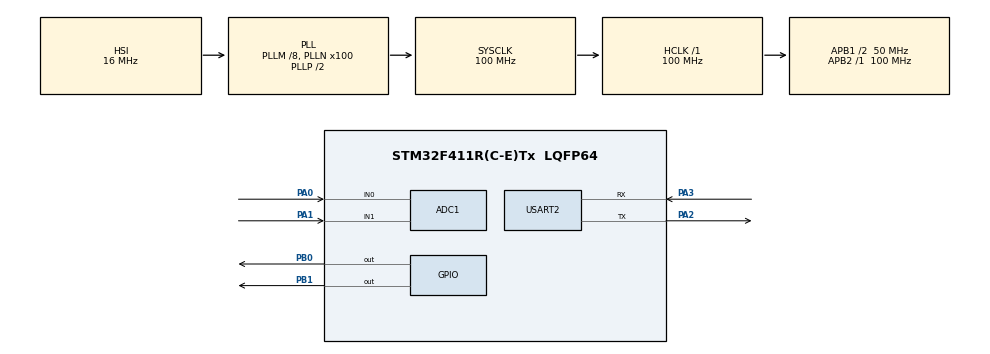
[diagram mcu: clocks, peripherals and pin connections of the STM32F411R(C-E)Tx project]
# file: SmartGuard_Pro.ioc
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ADC1.Channel-1\#ChannelRegularConversion=ADC_CHANNEL_0
ADC1.Channel-2\#ChannelRegularConversion=ADC_CHANNEL_1
ADC1.ContinuousConvMode=ENABLE
ADC1.NbrOfConversion=2
ADC1.NbrOfConversionFlag=1
ADC1.Rank-1\#ChannelRegularConversion=1
ADC1.Rank-2\#ChannelRegularConversion=2
ADC1.SamplingTime-1\#ChannelRegularConversion=ADC_SAMPLETIME_3CYCLES
ADC1.SamplingTime-2\#ChannelRegularConversion=ADC_SAMPLETIME_112CYCLES
ADC1.ScanConvMode=ENABLE
ADC1.master=1
Mcu.Family=STM32F4
Mcu.Name=STM32F411R(C-E)Tx
Mcu.Package=LQFP64
NVIC.PriorityGroup=NVIC_PRIORITYGROUP_4
PA0-WKUP.Signal=ADCx_IN0
PA1.Signal=ADCx_IN1
PA2.Mode=Asynchronous
PA2.Signal=USART2_TX
PA3.Mode=Asynchronous
PA3.Signal=USART2_RX
PB0.Signal=GPIO_Output
PB1.Signal=GPIO_Output
ProjectManager.HeapSize=0x200
ProjectManager.StackSize=0x400
ProjectManager.TargetToolchain=STM32CubeIDE
RCC.48MHZClocksFreq_Value=50000000
RCC.AHBFreq_Value=100000000
RCC.APB1CLKDivider=RCC_HCLK_DIV2
RCC.APB1Freq_Value=50000000
RCC.APB1TimFreq_Value=100000000
RCC.APB2Freq_Value=100000000
RCC.APB2TimFreq_Value=100000000
RCC.CortexFreq_Value=100000000
RCC.HCLKFreq_Value=100000000
RCC.HSE_VALUE=25000000
RCC.HSI_VALUE=16000000
RCC.LSE_VALUE=32768
RCC.PLLM=8
RCC.PLLN=100
RCC.SYSCLKFreq_VALUE=100000000
RCC.SYSCLKSource=RCC_SYSCLKSOURCE_PLLCLK
RCC.VCOOutputFreq_Value=200000000
SH.ADCx_IN0.0=ADC1_IN0,IN0
SH.ADCx_IN1.0=ADC1_IN1,IN1
USART2.VirtualMode=VM_ASYNC
board=NUCLEO-F411RE

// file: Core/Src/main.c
/* USER CODE BEGIN Header */
/**
  ******************************************************************************
  * @file           : main.c
  * @brief          : Main program body
  ******************************************************************************
  */
/* USER CODE END Header */
#include "main.h"
/* USER CODE BEGIN Includes */
#include <stdio.h>
/* USER CODE END Includes */

ADC_HandleTypeDef hadc1;

UART_HandleTypeDef huart2;

void SystemClock_Config(void);
static void MX_GPIO_Init(void);
static void MX_USART2_UART_Init(void);
static void MX_ADC1_Init(void);

/* USER CODE BEGIN 0 */
// Retarget printf to UART2
int __io_putchar(int ch)
{
  HAL_UART_Transmit(&huart2, (uint8_t *)&ch, 1, 0xFFFF);
  return ch;
}
/*    <-- DELETE THIS STRAY COMMENT START
/* USER CODE END 0 */
/*
/* USER CODE END 0 */

int main(void)
{
  HAL_Init();
  SystemClock_Config();
  MX_GPIO_Init();
  MX_USART2_UART_Init();
  MX_ADC1_Init();

  /* USER CODE BEGIN 2 */
  printf("SmartGuard Pro: Multisensor System Online\r\n");
  uint32_t val0 = 0;
  uint32_t val1 = 0;
  /* USER CODE END 2 */

  /* Infinite loop */
    while (1)
    {
      /* USER CODE BEGIN WHILE */
      uint32_t val0 = 0;
      uint32_t val1 = 0;
      float celsius = 0;

      HAL_ADC_Start(&hadc1);

      // Read Potentiometer (Channel 0)
      if (HAL_ADC_PollForConversion(&hadc1, 10) == HAL_OK) {
          val0 = HAL_ADC_GetValue(&hadc1);
      }

      // Read Temperature Sensor (Channel 1)
      if (HAL_ADC_PollForConversion(&hadc1, 10) == HAL_OK) {
          val1 = HAL_ADC_GetValue(&hadc1);
      }

      HAL_ADC_Stop(&hadc1);

      // --- Temperature Conversion Math ---
      // This formula converts the 12-bit ADC value to an approximate Celsius
      // assuming a 10k NTC thermistor and a 10k resistor divider.
      float voltage = val1 * (3.3f / 4095.0f);
      // Simple linear approximation: (Raw value / scale) + offset
      // You may need to tune '40.0' and '10.0' based on your specific sensor
      celsius = (float)(4095 - val1) / 50.0f + 10.0f;

      // --- Telemetry Dashboard ---
      // Note: use %.2f to print the float temperature
      printf("POT: %lu | TEMP: %.2f C\r\n", val0, celsius);

      // --- Industrial Safety Logic ---
      // Trigger alarm if Pot > 80% or Temp > 35 Degrees
      if (val0 > 3500 || celsius > 35.0f) {
          HAL_GPIO_WritePin(GPIOB, GPIO_PIN_0, GPIO_PIN_SET); // Buzzer
          HAL_GPIO_WritePin(GPIOB, GPIO_PIN_1, GPIO_PIN_SET); // Red LED
          printf("!!! ALERT: CRITICAL HEAT OR PRESSURE !!!\r\n");
      } else {
          HAL_GPIO_WritePin(GPIOB, GPIO_PIN_0, GPIO_PIN_RESET);
          HAL_GPIO_WritePin(GPIOB, GPIO_PIN_1, GPIO_PIN_RESET);
      }

      HAL_Delay(1000); // Sample every 1 second
      /* USER CODE END WHILE */
    }
}
void SystemClock_Config(void)
{
  RCC_OscInitTypeDef RCC_OscInitStruct = {0};
  RCC_ClkInitTypeDef RCC_ClkInitStruct = {0};

  /** Configure the main internal regulator output voltage
  */
  __HAL_RCC_PWR_CLK_ENABLE();
  __HAL_PWR_VOLTAGESCALING_CONFIG(PWR_REGULATOR_VOLTAGE_SCALE1);

  /** Initializes the RCC Oscillators according to the specified parameters
  * in the RCC_OscInitTypeDef structure.
  */
  RCC_OscInitStruct.OscillatorType = RCC_OSCILLATORTYPE_HSI;
  RCC_OscInitStruct.HSIState = RCC_HSI_ON;
  RCC_OscInitStruct.HSICalibrationValue = RCC_HSICALIBRATION_DEFAULT;
  RCC_OscInitStruct.PLL.PLLState = RCC_PLL_ON;
  RCC_OscInitStruct.PLL.PLLSource = RCC_PLLSOURCE_HSI;
  RCC_OscInitStruct.PLL.PLLM = 8;
  RCC_OscInitStruct.PLL.PLLN = 100;
  RCC_OscInitStruct.PLL.PLLP = RCC_PLLP_DIV2;
  RCC_OscInitStruct.PLL.PLLQ = 4;
  if (HAL_RCC_OscConfig(&RCC_OscInitStruct) != HAL_OK)
  {
    Error_Handler();
  }

  /** Initializes the CPU, AHB and APB buses clocks
  */
  RCC_ClkInitStruct.ClockType = RCC_CLOCKTYPE_HCLK|RCC_CLOCKTYPE_SYSCLK
                              |RCC_CLOCKTYPE_PCLK1|RCC_CLOCKTYPE_PCLK2;
  RCC_ClkInitStruct.SYSCLKSource = RCC_SYSCLKSOURCE_PLLCLK;
  RCC_ClkInitStruct.AHBCLKDivider = RCC_SYSCLK_DIV1;
  RCC_ClkInitStruct.APB1CLKDivider = RCC_HCLK_DIV2;
  RCC_ClkInitStruct.APB2CLKDivider = RCC_HCLK_DIV1;

  if (HAL_RCC_ClockConfig(&RCC_ClkInitStruct, FLASH_LATENCY_3) != HAL_OK)
  {
    Error_Handler();
  }
}

static void MX_ADC1_Init(void)
{

  ADC_ChannelConfTypeDef sConfig = {0};

  /** Configure the global features of the ADC (Clock, Resolution, Data Alignment and number of conversion)
  */
  hadc1.Instance = ADC1;
  hadc1.Init.ClockPrescaler = ADC_CLOCK_SYNC_PCLK_DIV4;
  hadc1.Init.Resolution = ADC_RESOLUTION_12B;
  hadc1.Init.ScanConvMode = ENABLE;
  hadc1.Init.ContinuousConvMode = ENABLE;
  hadc1.Init.DiscontinuousConvMode = DISABLE;
  hadc1.Init.ExternalTrigConvEdge = ADC_EXTERNALTRIGCONVEDGE_NONE;
  hadc1.Init.ExternalTrigConv = ADC_SOFTWARE_START;
  hadc1.Init.DataAlign = ADC_DATAALIGN_RIGHT;
  hadc1.Init.NbrOfConversion = 2;
  hadc1.Init.DMAContinuousRequests = DISABLE;
  hadc1.Init.EOCSelection = ADC_EOC_SINGLE_CONV;
  if (HAL_ADC_Init(&hadc1) != HAL_OK)
  {
    Error_Handler();
  }

  /** Configure for the selected ADC regular channel its corresponding rank in the sequencer and its sample time.
  */
  sConfig.Channel = ADC_CHANNEL_0;
  sConfig.Rank = 1;
  sConfig.SamplingTime = ADC_SAMPLETIME_3CYCLES;
  if (HAL_ADC_ConfigChannel(&hadc1, &sConfig) != HAL_OK)
  {
    Error_Handler();
  }

  /** Configure for the selected ADC regular channel its corresponding rank in the sequencer and its sample time.
  */
  sConfig.Channel = ADC_CHANNEL_1;
  sConfig.Rank = 2;
  sConfig.SamplingTime = ADC_SAMPLETIME_112CYCLES;
  if (HAL_ADC_ConfigChannel(&hadc1, &sConfig) != HAL_OK)
  {
    Error_Handler();
  }

}

static void MX_USART2_UART_Init(void)
{

  huart2.Instance = USART2;
  huart2.Init.BaudRate = 115200;
  huart2.Init.WordLength = UART_WORDLENGTH_8B;
  huart2.Init.StopBits = UART_STOPBITS_1;
  huart2.Init.Parity = UART_PARITY_NONE;
  huart2.Init.Mode = UART_MODE_TX_RX;
  huart2.Init.HwFlowCtl = UART_HWCONTROL_NONE;
  huart2.Init.OverSampling = UART_OVERSAMPLING_16;
  if (HAL_UART_Init(&huart2) != HAL_OK)
  {
    Error_Handler();
  }

}

static void MX_GPIO_Init(void)
{
  GPIO_InitTypeDef GPIO_InitStruct = {0};

  /* GPIO Ports Clock Enable */
  __HAL_RCC_GPIOA_CLK_ENABLE();
  __HAL_RCC_GPIOB_CLK_ENABLE();

  /*Configure GPIO pin Output Level */
  HAL_GPIO_WritePin(GPIOB, GPIO_PIN_0|GPIO_PIN_1, GPIO_PIN_RESET);

  /*Configure GPIO pins : PB0 PB1 */
  GPIO_InitStruct.Pin = GPIO_PIN_0|GPIO_PIN_1;
  GPIO_InitStruct.Mode = GPIO_MODE_OUTPUT_PP;
  GPIO_InitStruct.Pull = GPIO_NOPULL;
  GPIO_InitStruct.Speed = GPIO_SPEED_FREQ_LOW;
  HAL_GPIO_Init(GPIOB, &GPIO_InitStruct);

}

void Error_Handler(void)
{
  __disable_irq();
  while (1)
  {
  }
}
